# ATmega328PB register map
Vendor: Atmel; File version: 1.0
CPU: other r0p0, little endian, no MPU, no FPU, 4 interrupt priority bits
Registers are 8-bit, read-write, reset 0x0 unless marked. A register's access mark holds for its fields unless they carry their own. Offsets are from the block's base; lines under a group give offsets from that group; [hi:lo] are bit positions; {n}, {i} and the like mark numbered series; 'fields as' and 'values as' point back to an identical list; <NAME> marks a mode.

## Memory map
0x00000000 FUSE size 0x3 — Fuses
0x00000000 LOCKBIT size 0x1 — Lockbits
0x00000023 PORTB size 0x3 — I/O Port
0x00000026 PORTC size 0x3 — I/O Port
0x00000029 PORTD size 0x3 — I/O Port
0x0000002C PORTE size 0x3 — I/O Port
0x00000035 TC0 blocks up to offset 0x3A
0x00000036 TC1 blocks up to offset 0x56
0x00000037 TC2 blocks up to offset 0x80 — Timer/Counter, 8-bit Async
0x00000038 TC3 blocks up to offset 0x64
0x00000039 TC4 blocks up to offset 0x73
0x0000003B EXINT blocks up to offset 0x39
0x0000003E CPU blocks up to offset 0x29
0x0000003F EEPROM size 0x4
0x0000004C SPI0 size 0x3
0x0000004F AC blocks up to offset 0x31
0x00000060 WDT size 0x1
0x00000062 CFD size 0x1
0x00000078 ADC blocks up to offset 0x7 — Analog-to-Digital Converter
0x000000AC SPI1 size 0x3
0x000000B8 TWI0 size 0x6 — Two Wire Serial Interface
0x000000C0 USART0 size 0x7 — USART
0x000000C8 USART1 size 0x7 — USART
0x000000D8 TWI1 size 0x6 — Two Wire Serial Interface

## Interrupts
0 RESET (CPU) — External Pin, Power-on Reset, Brown-out Reset and Watchdog Reset
1 INT0 (CPU) — External Interrupt Request 0
2 INT1 (CPU) — External Interrupt Request 1
3 PCINT0 (CPU) — Pin Change Interrupt Request 0
4 PCINT1 (CPU) — Pin Change Interrupt Request 1
5 PCINT2 (CPU) — Pin Change Interrupt Request 2
6 WDT (CPU) — Watchdog Time-out Interrupt
7 TIMER2_COMPA (CPU) — Timer/Counter2 Compare Match A
8 TIMER2_COMPB (CPU) — Timer/Counter2 Compare Match B
9 TIMER2_OVF (CPU) — Timer/Counter2 Overflow
10 TIMER1_CAPT (CPU) — Timer/Counter1 Capture Event
11 TIMER1_COMPA (CPU) — Timer/Counter1 Compare Match A
12 TIMER1_COMPB (CPU) — Timer/Counter1 Compare Match B
13 TIMER1_OVF (CPU) — Timer/Counter1 Overflow
14 TIMER0_COMPA (CPU) — TimerCounter0 Compare Match A
15 TIMER0_COMPB (CPU) — TimerCounter0 Compare Match B
16 TIMER0_OVF (CPU) — Timer/Counter0 Overflow
17 SPI0_STC (CPU) — SPI Serial Transfer Complete
18 USART0_RX (CPU) — USART0 Rx Complete
19 USART0_UDRE (CPU) — USART0, Data Register Empty
20 USART0_TX (CPU) — USART0 Tx Complete
21 ADC (CPU) — ADC Conversion Complete
22 EE_READY (CPU) — EEPROM Ready
23 ANALOG_COMP (CPU) — Analog Comparator
24 TWI0 (CPU) — Two-wire Serial Interface
25 SPM_Ready (CPU) — Store Program Memory Read
26 USART0_START (CPU) — USART0 Start frame detection
27 PCINT3 (CPU) — Pin Change Interrupt Request 3
28 USART1_RX (CPU) — USART1 Rx Complete
29 USART1_UDRE (CPU) — USART1, Data Register Empty
30 USART1_TX (CPU) — USART1 Tx Complete
31 USART1_START (CPU) — USART1 Start frame detection
32 TIMER3_CAPT (CPU) — Timer/Counter3 Capture Event
33 TIMER3_COMPA (CPU) — Timer/Counter3 Compare Match A
34 TIMER3_COMPB (CPU) — Timer/Counter3 Compare Match B
35 TIMER3_OVF (CPU) — Timer/Counter3 Overflow
36 CFD (CPU) — Clock failure detection interrupt
37 PTC_EOC (CPU) — PTC End of conversion
38 PTC_WCOMP (CPU) — PTC Window comparator mode
39 SPI1_STC (CPU) — SPI1 Serial Transfer Complete
40 TWI1 (CPU) — TWI Transfer Complete
41 TIMER4_CAPT (CPU) — Timer/Counter4 Capture Event
42 TIMER4_COMPA (CPU) — Timer/Counter4 Compare Match A
43 TIMER4_COMPB (CPU) — Timer/Counter4 Compare Match B
44 TIMER4_OVF (CPU) — Timer/Counter4 Overflow

## AC
Base 0x0000004F
0x00 ACSRB — Analog Comparator Control And Status Register-B
  [0] ACOE — Analog Comparator Output Enable
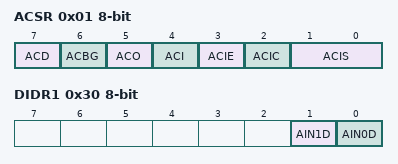
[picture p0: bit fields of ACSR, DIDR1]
0x01 ACSR — Analog Comparator Control And Status Register
  [7] ACD — Analog Comparator Disable
  [6] ACBG — Analog Comparator Bandgap Select
  [5] ACO — Analog Compare Output
  [4] ACI — Analog Comparator Interrupt Flag
  [3] ACIE — Analog Comparator Interrupt Enable
  [2] ACIC — Analog Comparator Input Capture Enable
  [1:0] ACIS — Analog Comparator Interrupt Mode Select bits
    0=INTERRUPT_ON_TOGGLE; 2=INTERRUPT_ON_FALLING_EDGE; 3=INTERRUPT_ON_RISING_EDGE
0x01 ACSRA — Analog Comparator Control And Status Register-A
0x30 DIDR1 — Digital Input Disable Register 1
  [1] AIN1D — AIN1 Digital Input Disable
  [0] AIN0D — AIN0 Digital Input Disable
